# STM32WLE5_CM4 register map
File version: 1.4
CPU: CM4 r0p1, little endian, MPU, FPU, 4 interrupt priority bits
Registers are 32-bit, read-write, reset 0x0 unless marked. A register's access mark holds for its fields unless they carry their own. Offsets are from the block's base; [hi:lo] are bit positions; {n}, {i} and the like mark numbered series.

## SYSCFG_continue — System configuration controller
Base 0x40010100
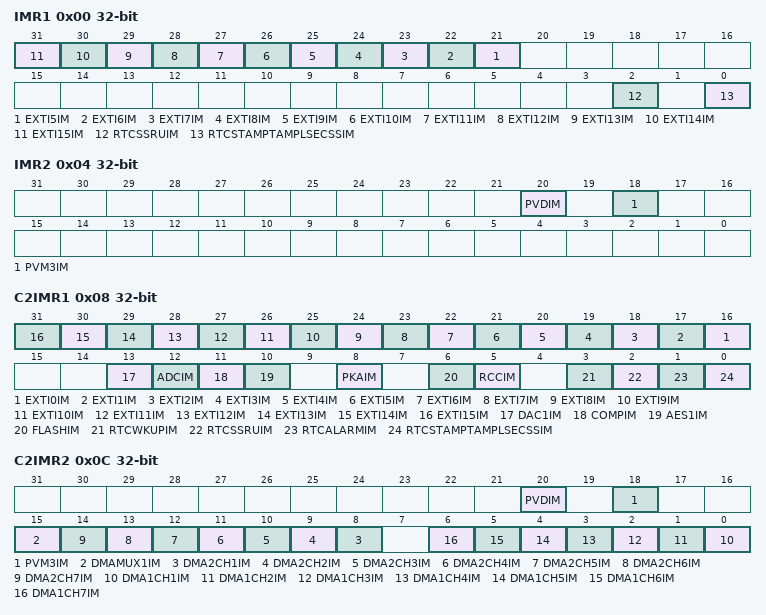
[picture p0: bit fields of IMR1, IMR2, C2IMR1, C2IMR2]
0x00 IMR1
  [n+16] EXTI{n}IM (n=5..15) — Peripheral EXTI{n} interrupt mask to CPU1
  [2] RTCSSRUIM
  [0] RTCSTAMPTAMPLSECSSIM
0x04 IMR2
  [20] PVDIM — Peripheral xxx interrupt mask to CPU1
  [18] PVM3IM — Peripheral xxx interrupt mask to CPU1
0x08 C2IMR1
  [n+16] EXTI{n}IM (n=0..15) — Peripheral EXTI{n} interrupt mask to CPU2
  [13] DAC1IM — Peripheral DAC1 interrupt mask to CPU2
  [12] ADCIM — Peripheral ADC interrupt mask to CPU2
  [11] COMPIM — Peripheral COMP interrupt mask to CPU2
  [10] AES1IM
  [8] PKAIM
  [6] FLASHIM — Peripheral FLASH interrupt mask to CPU2
  [5] RCCIM — Peripheral RCC interrupt mask to CPU2
  [3] RTCWKUPIM — Peripheral RTCWKUP interrupt mask to CPU2
  [2] RTCSSRUIM
  [1] RTCALARMIM — Peripheral RTCALARM interrupt mask to CPU2
  [0] RTCSTAMPTAMPLSECSSIM — Peripheral RTCSTAMPTAMPLSECSS interrupt mask to CPU2
0x0C C2IMR2
  [20] PVDIM — Peripheral PVD interrupt mask to CPU2
  [18] PVM3IM — Peripheral PVM3 interrupt mask to CPU2
  [15] DMAMUX1IM — Peripheral DMAMUX1 interrupt mask to CPU2
  [n+7] DMA2CH{n}IM (n=1..7) — Peripheral DMA2CH{n} interrupt mask to CPU2
  [n-1] DMA1CH{n}IM (n=1..7) — Peripheral DMA1CH{n} interrupt mask to CPU2

## TAMP — Tamper and backup registers
Base 0x4000B000
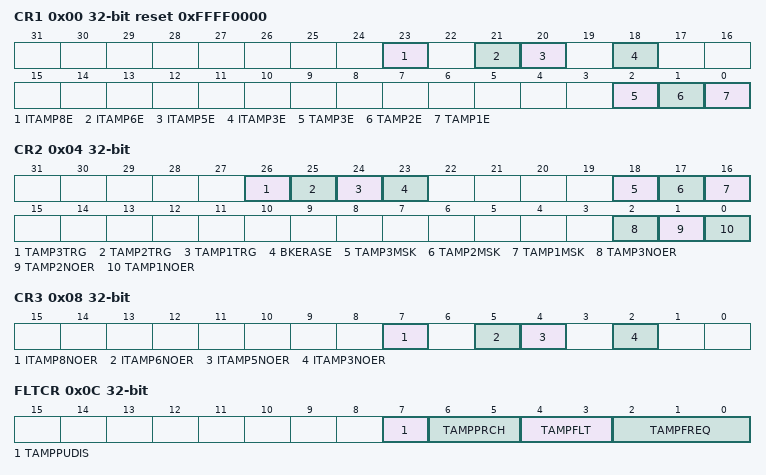
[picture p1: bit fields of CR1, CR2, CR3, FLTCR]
0x00 CR1 reset 0xFFFF0000 — control register 1
  [23] ITAMP8E
  [21] ITAMP6E
  [20] ITAMP5E
  [18] ITAMP3E
  [2] TAMP3E — TAMP2E
  [1] TAMP2E
  [0] TAMP1E
0x04 CR2 — control register 2
  [26] TAMP3TRG
  [25] TAMP2TRG
  [24] TAMP1TRG
  [23] BKERASE — Backup registerserase
  [18] TAMP3MSK
  [17] TAMP2MSK
  [16] TAMP1MSK
  [2] TAMP3NOER
  [1] TAMP2NOER
  [0] TAMP1NOER
0x08 CR3 — TAMP control register 3
  [7] ITAMP8NOER, [5] ITAMP6NOER, [4] ITAMP5NOER, [2] ITAMP3NOER
0x0C FLTCR — TAMP filter control register
  [7] TAMPPUDIS, [6:5] TAMPPRCH, [4:3] TAMPFLT, [2:0] TAMPFREQ
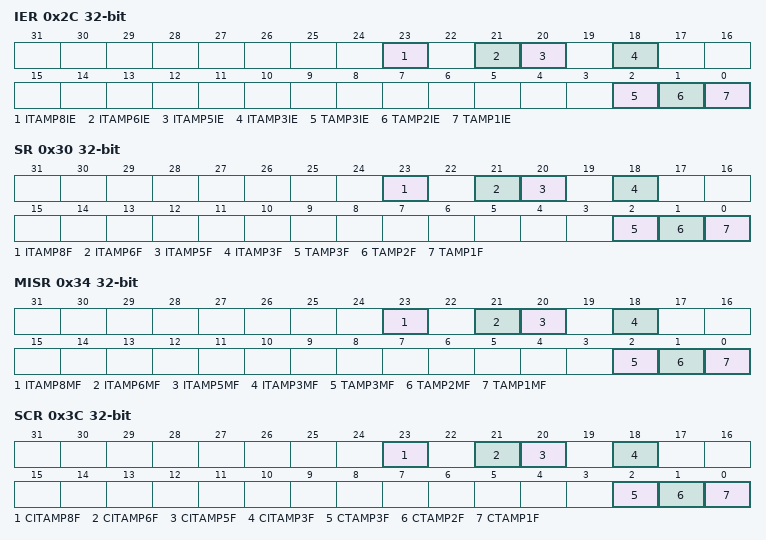
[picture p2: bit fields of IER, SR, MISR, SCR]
0x2C IER — TAMP interrupt enable register
  [23] ITAMP8IE, [21] ITAMP6IE, [20] ITAMP5IE, [18] ITAMP3IE, [2] TAMP3IE, [1] TAMP2IE, [0] TAMP1IE
0x30 SR ro — TAMP status register
  [23] ITAMP8F, [21] ITAMP6F, [20] ITAMP5F, [18] ITAMP3F, [2] TAMP3F, [1] TAMP2F, [0] TAMP1F
0x34 MISR ro — TAMP masked interrupt status register
  [23] ITAMP8MF, [21] ITAMP6MF, [20] ITAMP5MF, [18] ITAMP3MF, [2] TAMP3MF, [1] TAMP2MF, [0] TAMP1MF
0x3C SCR wo — TAMP status clear register
  [23] CITAMP8F, [21] CITAMP6F, [20] CITAMP5F, [18] CITAMP3F, [2] CTAMP3F, [1] CTAMP2F, [0] CTAMP1F
0x40 COUNTR ro — monotonic counter register
  [31:0] COUNT
{0x100+4i} BKP{i}R (i=0..9) — TAMP backup register
  [31:0] BKP
{0x118+4i} BKP{i}R (i=10..19) — TAMP backup register
  [31:0] BKP

## TIM16 — General-purpose timers
Base 0x40014400
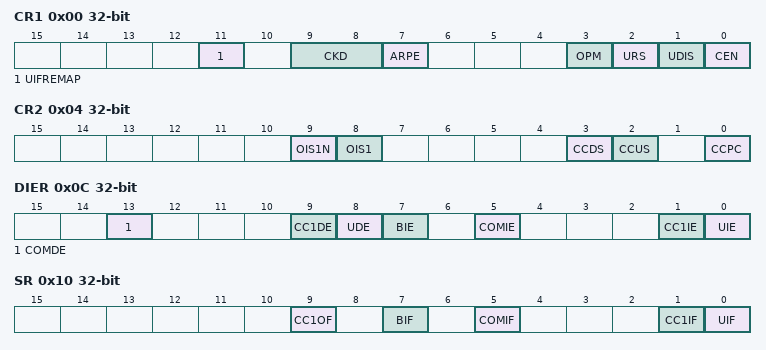
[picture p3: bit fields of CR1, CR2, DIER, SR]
0x00 CR1 — TIM16/TIM17 control register 1
  [11] UIFREMAP — UIF status bit remapping
  [9:8] CKD — Clock division
  [7] ARPE — Auto-reload preload enable
  [3] OPM — One pulse mode
  [2] URS — Update request source
  [1] UDIS — Update disable
  [0] CEN — Counter enable
0x04 CR2 — TIM16/TIM17 control register 2
  [9] OIS1N, [8] OIS1, [3] CCDS, [2] CCUS, [0] CCPC
0x0C DIER — TIM16/TIM17 DMA/interrupt enable register
  [13] COMDE — COM DMA request enable
  [9] CC1DE — Capture/Compare 1 DMA request enable
  [8] UDE — Update DMA request enable
  [7] BIE — Break interrupt enable
  [5] COMIE — COM interrupt enable
  [1] CC1IE — Capture/Compare 1 interrupt enable
  [0] UIE — Update interrupt enable
0x10 SR — TIM16/TIM17 status register
  [9] CC1OF — Capture/Compare 1 overcapture flag
  [7] BIF — Break interrupt flag
  [5] COMIF — COM interrupt flag
  [1] CC1IF — Capture/Compare 1 interrupt flag
  [0] UIF — Update interrupt flag
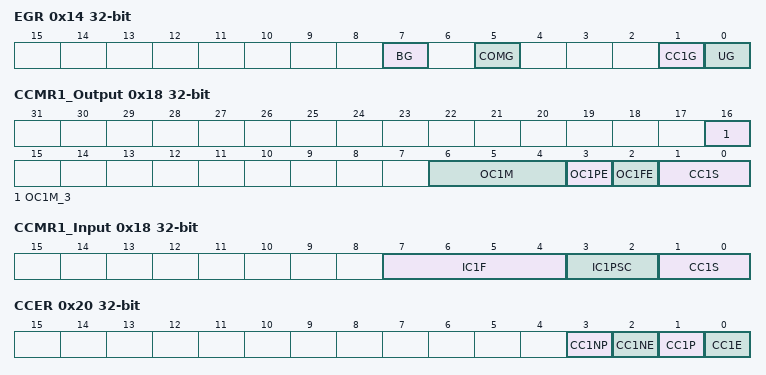
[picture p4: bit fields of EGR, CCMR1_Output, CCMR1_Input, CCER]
0x14 EGR wo — TIM16/TIM17 event generation register
  [7] BG — Break generation
  [5] COMG — Capture/Compare control update generation
  [1] CC1G — Capture/Compare 1 generation
  [0] UG — Update generation
0x18 CCMR1_Output — TIM16/TIM17 capture/compare mode register 1
  [16] OC1M_3 — OC1M
  [6:4] OC1M
  [3] OC1PE
  [2] OC1FE
  [1:0] CC1S
0x18 CCMR1_Input (alternate view of CCMR1_Output) — TIM16/TIM17 capture/compare mode register 1
  [7:4] IC1F, [3:2] IC1PSC, [1:0] CC1S
0x20 CCER — TIM16/TIM17 capture/compare enable register
  [3] CC1NP — Capture/Compare 1 complementary output polarity
  [2] CC1NE — Capture/Compare 1 complementary output enable
  [1] CC1P — Capture/Compare 1 output polarity
  [0] CC1E — Capture/Compare 1 output enable
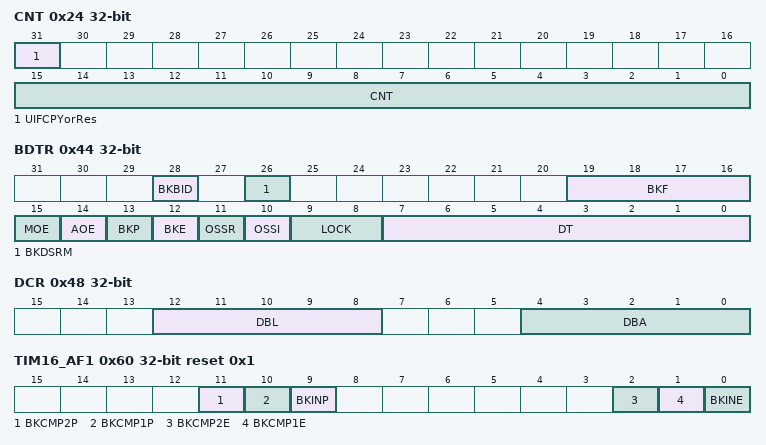
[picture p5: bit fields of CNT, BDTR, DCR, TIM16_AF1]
0x24 CNT access per field — TIM16/TIM17 counter
  [31] UIFCPYorRes ro — UIF Copy
  [15:0] CNT rw
0x28 PSC — TIM16/TIM17 prescaler
  [15:0] PSC — Prescaler value
0x2C ARR reset 0xFFFF — TIM16/TIM17 auto-reload register
  [15:0] ARR — Auto-reload value
0x30 RCR — TIM16/TIM17 repetition counter register
  [7:0] REP — Repetition counter value
0x34 CCR1 — TIM16/TIM17 capture/compare register 1
  [15:0] CCR1 — Capture/Compare 1 value
0x44 BDTR — TIM16/TIM17 break and dead-time register
  [28] BKBID — Break Bidirectional
  [26] BKDSRM — Break Disarm
  [19:16] BKF — Break filter
  [15] MOE — Main output enable
  [14] AOE — Automatic output enable
  [13] BKP — Break polarity
  [12] BKE — Break enable
  [11] OSSR — Off-state selection for Run mode
  [10] OSSI — Off-state selection for Idle mode
  [9:8] LOCK — Lock configuration
  [7:0] DT — Dead-time generator setup
0x48 DCR — TIM16/TIM17 DMA control register
  [12:8] DBL — DMA burst length
  [4:0] DBA — DMA base address
0x4C DMAR — TIM16/TIM17 DMA address for full transfer
  [15:0] DMAB — DMA register for burst accesses
0x50 TIM16_OR1 — TIM16 option register 1
  [1:0] TI1_RMP — Timer 17 input 1 connection
0x60 TIM16_AF1 reset 0x1 — TIM16 alternate function register 1
  [11] BKCMP2P — BRK COMP2 input polarity
  [10] BKCMP1P — BRK COMP1 input polarity
  [9] BKINP — BRK BKIN input polarity
  [2] BKCMP2E — BRK COMP2 enable
  [1] BKCMP1E — BRK COMP1 enable
  [0] BKINE — BRK BKIN input enable
0x68 TIM16_TISEL — TIM16 input selection register
  [3:0] TISEL
